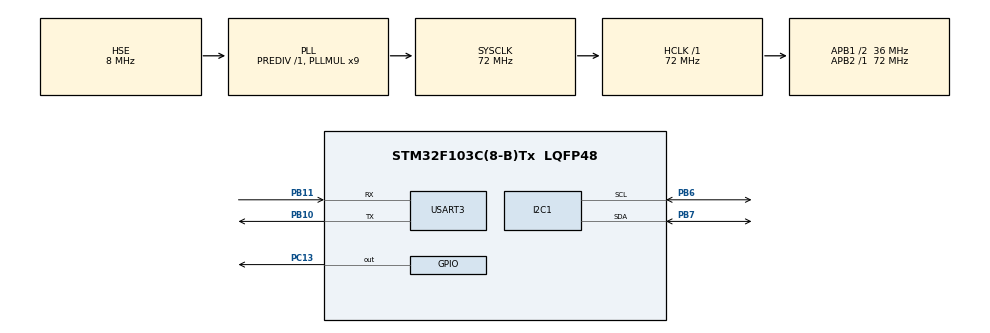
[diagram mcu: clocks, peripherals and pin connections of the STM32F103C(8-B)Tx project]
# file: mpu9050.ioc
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I2C1.I2C_Mode=I2C_Fast
Mcu.Family=STM32F1
Mcu.Name=STM32F103C(8-B)Tx
Mcu.Package=LQFP48
NVIC.PriorityGroup=NVIC_PRIORITYGROUP_4
NVIC.TIM1_BRK_IRQn=true\:0\:0\:false\:false\:true\:true\:true\:true
NVIC.TIM1_CC_IRQn=true\:0\:0\:false\:false\:true\:true\:true\:true
NVIC.TIM1_TRG_COM_IRQn=true\:0\:0\:false\:false\:true\:true\:true\:true
NVIC.TIM1_UP_IRQn=true\:0\:0\:false\:false\:true\:true\:true\:true
NVIC.USART3_IRQn=true\:0\:0\:false\:false\:true\:true\:true\:true
PA13.Mode=Serial_Wire
PA13.Signal=SYS_JTMS-SWDIO
PA14.Mode=Serial_Wire
PA14.Signal=SYS_JTCK-SWCLK
PB10.Mode=Asynchronous
PB10.Signal=USART3_TX
PB11.Mode=Asynchronous
PB11.Signal=USART3_RX
PB6.Mode=I2C
PB6.Signal=I2C1_SCL
PB7.Mode=I2C
PB7.Signal=I2C1_SDA
PC13-TAMPER-RTC.Signal=GPIO_Output
PD0-OSC_IN.Mode=HSE-External-Oscillator
PD0-OSC_IN.Signal=RCC_OSC_IN
PD1-OSC_OUT.Mode=HSE-External-Oscillator
PD1-OSC_OUT.Signal=RCC_OSC_OUT
ProjectManager.HeapSize=0x200
ProjectManager.StackSize=0x400
ProjectManager.TargetToolchain=MDK-ARM V5.32
RCC.AHBFreq_Value=72000000
RCC.APB1CLKDivider=RCC_HCLK_DIV2
RCC.APB1Freq_Value=36000000
RCC.APB1TimFreq_Value=72000000
RCC.APB2Freq_Value=72000000
RCC.APB2TimFreq_Value=72000000
RCC.HCLKFreq_Value=72000000
RCC.PLLMUL=RCC_PLL_MUL9
RCC.PLLSourceVirtual=RCC_PLLSOURCE_HSE
RCC.SYSCLKFreq_VALUE=72000000
RCC.SYSCLKSource=RCC_SYSCLKSOURCE_PLLCLK
RCC.USBFreq_Value=72000000
TIM1.Period=99
TIM1.Prescaler=7199
TIM3.Period=99
TIM3.Prescaler=7199
USART3.VirtualMode=VM_ASYNC
VP_TIM1_VS_ClockSourceINT.Mode=Internal
VP_TIM3_VS_ClockSourceINT.Mode=Internal
board=custom

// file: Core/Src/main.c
/* USER CODE BEGIN Header */
/**
  ******************************************************************************
  * @file           : main.c
  * @brief          : Main program body
  ******************************************************************************
  * @attention
  *
  * Copyright (c) 2022 STMicroelectronics.
  * All rights reserved.
  *
  * This software is licensed under terms that can be found in the LICENSE file
  * in the root directory of this software component.
  * If no LICENSE file comes with this software, it is provided AS-IS.
  *
  ******************************************************************************
  */
/* USER CODE END Header */
#include "main.h"
#include "MPU9250.h"
#include "MPU9250_register.h"
#include "Madgwick.h"
#include "stdlib.h"
#include "string.h"
#include "stdio.h"
#include "math.h"

#define pi 3.141592653589793238462
float q[4] = {1.0f, 0.0f, 0.0f, 0.0f};
float a12, a22, a31, a32, a33;
uint8_t buf[100]={0};

float roll,yaw,pitch;
extern uint8_t temp;
extern char buff;

extern int16_t Mag_x,Mag_y,Mag_z;

extern int16_t Accel_x,Accel_y,Accel_z,Gyro_x,Gyro_y,Gyro_z;
extern int32_t Accel_x_bias,Accel_y_bias,Accel_z_bias,Gyro_x_bias,Gyro_y_bias,Gyro_z_bias;
extern float asax,asay,asaz;
extern float mag_offset[3] ;
extern float Accel_X,Accel_Y,Accel_Z,Gyro_X,Gyro_Y,Gyro_Z;
extern float Mag_X_calib,Mag_Y_calib,Mag_Z_calib;
extern int32_t mag_bias[3] , mag_scale[3];
extern float scale_x ,scale_y,scale_z;

I2C_HandleTypeDef hi2c1;

TIM_HandleTypeDef htim1;
TIM_HandleTypeDef htim3;

UART_HandleTypeDef huart3;

void SystemClock_Config(void);
static void MX_GPIO_Init(void);
static void MX_I2C1_Init(void);
static void MX_TIM1_Init(void);
static void MX_TIM3_Init(void);
static void MX_USART3_UART_Init(void);

/* USER CODE BEGIN 0 */
void HAL_TIM_PeriodElapsedCallback(TIM_HandleTypeDef *htim)
{

}
/* USER CODE END 0 */

int main(void)
{

  HAL_Init();

  /* Configure the system clock */
  SystemClock_Config();

  /* Initialize all configured peripherals */
  MX_GPIO_Init();
  MX_I2C1_Init();
  MX_TIM1_Init();
  MX_TIM3_Init();
  MX_USART3_UART_Init();
  /* USER CODE BEGIN 2 */
	init_IMU();
  init_magnetometer();

  if (Check_Connection(0x75) == 1)
  {
//	  sprintf((char*)buf,"Value of WHO_I_AM:0x%x\n\r",temp);
//	  HAL_UART_Transmit(&huart3,(uint8_t*)buf,sizeof(buf),1000);
//	  HAL_UART_Transmit(&huart3,(uint8_t*)"MPU9250 is online...\n\r",24,1000);
	  Calibration_IMU();
	  HAL_Delay(1000);
  }
  else
  {
	 // HAL_UART_Transmit(&huart3,(uint8_t*)"check connection...\n",22,1000);
  }

  Calib_magnetometer();
  /* USER CODE END 2 */
	HAL_TIM_Base_Start_IT(&htim3);
  HAL_TIM_Base_Start_IT(&htim1);
  /* Infinite loop */
  /* USER CODE BEGIN WHILE */
  while (1)
  {

		Process_IMU();

		q[0] = q0;
		q[1] = q1;
		q[2] = q2;
		q[3] = q3;
		a12 =   2.0f * (q[1] * q[2] + q[0] * q[3]);
		a22 =   q[0] * q[0] + q[1] * q[1] - q[2] * q[2] - q[3] * q[3];
		a31 =   2.0f * (q[0] * q[1] + q[2] * q[3]);
		a32 =   2.0f * (q[1] * q[3] - q[0] * q[2]);
		a33 =   q[0] * q[0] - q[1] * q[1] - q[2] * q[2] + q[3] * q[3];
		float sinp = a32;
		if (fabsf(sinp) >= 1)
			pitch = copysign(M_PI/2,sinp);
		else
			pitch =  asin(sinp);
		//pitch = -asinf(a32);
		roll  = atan2f(a31, a33);
		yaw   = atan2f(a12, a22);
		pitch *= 180.0f / pi;
		yaw = atan2f(sinf(yaw),cosf(yaw));
		yaw   *= 180.0f / pi;

		roll  *= 180.0f / pi;

  }
}

void SystemClock_Config(void)
{
  RCC_OscInitTypeDef RCC_OscInitStruct = {0};
  RCC_ClkInitTypeDef RCC_ClkInitStruct = {0};

  /** Initializes the RCC Oscillators according to the specified parameters
  * in the RCC_OscInitTypeDef structure.
  */
  RCC_OscInitStruct.OscillatorType = RCC_OSCILLATORTYPE_HSE;
  RCC_OscInitStruct.HSEState = RCC_HSE_ON;
  RCC_OscInitStruct.HSEPredivValue = RCC_HSE_PREDIV_DIV1;
  RCC_OscInitStruct.HSIState = RCC_HSI_ON;
  RCC_OscInitStruct.PLL.PLLState = RCC_PLL_ON;
  RCC_OscInitStruct.PLL.PLLSource = RCC_PLLSOURCE_HSE;
  RCC_OscInitStruct.PLL.PLLMUL = RCC_PLL_MUL9;
  if (HAL_RCC_OscConfig(&RCC_OscInitStruct) != HAL_OK)
  {
    Error_Handler();
  }

  /** Initializes the CPU, AHB and APB buses clocks
  */
  RCC_ClkInitStruct.ClockType = RCC_CLOCKTYPE_HCLK|RCC_CLOCKTYPE_SYSCLK
                              |RCC_CLOCKTYPE_PCLK1|RCC_CLOCKTYPE_PCLK2;
  RCC_ClkInitStruct.SYSCLKSource = RCC_SYSCLKSOURCE_PLLCLK;
  RCC_ClkInitStruct.AHBCLKDivider = RCC_SYSCLK_DIV1;
  RCC_ClkInitStruct.APB1CLKDivider = RCC_HCLK_DIV2;
  RCC_ClkInitStruct.APB2CLKDivider = RCC_HCLK_DIV1;

  if (HAL_RCC_ClockConfig(&RCC_ClkInitStruct, FLASH_LATENCY_2) != HAL_OK)
  {
    Error_Handler();
  }
}

static void MX_I2C1_Init(void)
{

  hi2c1.Instance = I2C1;
  hi2c1.Init.ClockSpeed = 400000;
  hi2c1.Init.DutyCycle = I2C_DUTYCYCLE_2;
  hi2c1.Init.OwnAddress1 = 0;
  hi2c1.Init.AddressingMode = I2C_ADDRESSINGMODE_7BIT;
  hi2c1.Init.DualAddressMode = I2C_DUALADDRESS_DISABLE;
  hi2c1.Init.OwnAddress2 = 0;
  hi2c1.Init.GeneralCallMode = I2C_GENERALCALL_DISABLE;
  hi2c1.Init.NoStretchMode = I2C_NOSTRETCH_DISABLE;
  if (HAL_I2C_Init(&hi2c1) != HAL_OK)
  {
    Error_Handler();
  }

}

static void MX_TIM1_Init(void)
{

  TIM_ClockConfigTypeDef sClockSourceConfig = {0};
  TIM_MasterConfigTypeDef sMasterConfig = {0};

  htim1.Instance = TIM1;
  htim1.Init.Prescaler = 7199;
  htim1.Init.CounterMode = TIM_COUNTERMODE_UP;
  htim1.Init.Period = 99;
  htim1.Init.ClockDivision = TIM_CLOCKDIVISION_DIV1;
  htim1.Init.RepetitionCounter = 0;
  htim1.Init.AutoReloadPreload = TIM_AUTORELOAD_PRELOAD_DISABLE;
  if (HAL_TIM_Base_Init(&htim1) != HAL_OK)
  {
    Error_Handler();
  }
  sClockSourceConfig.ClockSource = TIM_CLOCKSOURCE_INTERNAL;
  if (HAL_TIM_ConfigClockSource(&htim1, &sClockSourceConfig) != HAL_OK)
  {
    Error_Handler();
  }
  sMasterConfig.MasterOutputTrigger = TIM_TRGO_RESET;
  sMasterConfig.MasterSlaveMode = TIM_MASTERSLAVEMODE_DISABLE;
  if (HAL_TIMEx_MasterConfigSynchronization(&htim1, &sMasterConfig) != HAL_OK)
  {
    Error_Handler();
  }

}

static void MX_TIM3_Init(void)
{

  TIM_ClockConfigTypeDef sClockSourceConfig = {0};
  TIM_MasterConfigTypeDef sMasterConfig = {0};

  htim3.Instance = TIM3;
  htim3.Init.Prescaler = 7199;
  htim3.Init.CounterMode = TIM_COUNTERMODE_UP;
  htim3.Init.Period = 99;
  htim3.Init.ClockDivision = TIM_CLOCKDIVISION_DIV1;
  htim3.Init.AutoReloadPreload = TIM_AUTORELOAD_PRELOAD_DISABLE;
  if (HAL_TIM_Base_Init(&htim3) != HAL_OK)
  {
    Error_Handler();
  }
  sClockSourceConfig.ClockSource = TIM_CLOCKSOURCE_INTERNAL;
  if (HAL_TIM_ConfigClockSource(&htim3, &sClockSourceConfig) != HAL_OK)
  {
    Error_Handler();
  }
  sMasterConfig.MasterOutputTrigger = TIM_TRGO_RESET;
  sMasterConfig.MasterSlaveMode = TIM_MASTERSLAVEMODE_DISABLE;
  if (HAL_TIMEx_MasterConfigSynchronization(&htim3, &sMasterConfig) != HAL_OK)
  {
    Error_Handler();
  }

}

static void MX_USART3_UART_Init(void)
{

  huart3.Instance = USART3;
  huart3.Init.BaudRate = 115200;
  huart3.Init.WordLength = UART_WORDLENGTH_8B;
  huart3.Init.StopBits = UART_STOPBITS_1;
  huart3.Init.Parity = UART_PARITY_NONE;
  huart3.Init.Mode = UART_MODE_TX_RX;
  huart3.Init.HwFlowCtl = UART_HWCONTROL_NONE;
  huart3.Init.OverSampling = UART_OVERSAMPLING_16;
  if (HAL_UART_Init(&huart3) != HAL_OK)
  {
    Error_Handler();
  }

}

static void MX_GPIO_Init(void)
{
  GPIO_InitTypeDef GPIO_InitStruct = {0};

  /* GPIO Ports Clock Enable */
  __HAL_RCC_GPIOC_CLK_ENABLE();
  __HAL_RCC_GPIOD_CLK_ENABLE();
  __HAL_RCC_GPIOB_CLK_ENABLE();
  __HAL_RCC_GPIOA_CLK_ENABLE();

  /*Configure GPIO pin Output Level */
  HAL_GPIO_WritePin(GPIOC, GPIO_PIN_13, GPIO_PIN_RESET);

  /*Configure GPIO pin : PC13 */
  GPIO_InitStruct.Pin = GPIO_PIN_13;
  GPIO_InitStruct.Mode = GPIO_MODE_OUTPUT_PP;
  GPIO_InitStruct.Pull = GPIO_NOPULL;
  GPIO_InitStruct.Speed = GPIO_SPEED_FREQ_LOW;
  HAL_GPIO_Init(GPIOC, &GPIO_InitStruct);

}

void Error_Handler(void)
{
  __disable_irq();
  while (1)
  {
  }
}
